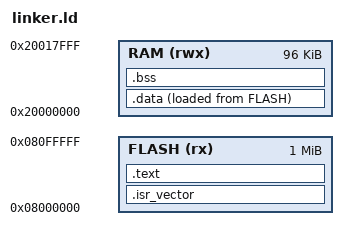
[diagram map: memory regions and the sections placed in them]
ENTRY(Reset_Handler)


_Min_Heap_Size  = 0x1000;   
_Min_Stack_Size = 0x1000;   

MEMORY
{
    FLASH (rx) : ORIGIN = 0x08000000, LENGTH = 1024K
    RAM (rwx)  : ORIGIN = 0x20000000, LENGTH = 96K
}

_estack = ORIGIN(RAM) +  LENGTH(RAM);


SECTIONS
{
    .isr_vector :
    {
        . = ALIGN(128);
        KEEP(*(.isr_vector))
    } > FLASH

    .text :
    {
        *(.text*)
        *(.rodata*)
        . = ALIGN(4);
        _etext = .;
    } > FLASH

    .data :
    {
        _sdata = .;
        *(.data*)
        _edata = .;
    } > RAM AT > FLASH

    _sidata = LOADADDR(.data);

    .bss :
    {
        _sbss = .;
        *(.bss*)
        *(COMMON)
        _ebss = .;
    } > RAM
}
